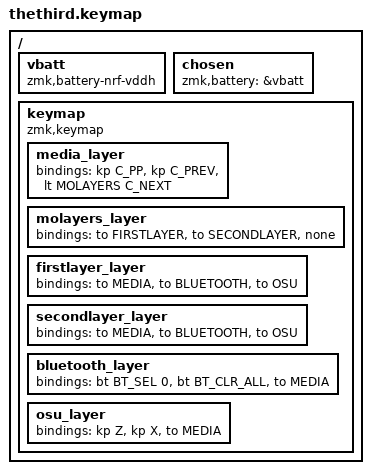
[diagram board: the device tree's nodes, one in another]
#include <behaviors.dtsi>
#include <dt-bindings/zmk/keys.h>
#include <dt-bindings/zmk/bt.h>
#include <dt-bindings/zmk/outputs.h>
#include <dt-bindings/zmk/ext_power.h>

#define MEDIA 0
#define MOLAYERS 1
#define FIRSTLAYER 2
#define SECONDLAYER 3
#define BLUETOOTH 4
#define OSU 5

/ {
    vbatt: vbatt {
                compatible = "zmk,battery-nrf-vddh";
        };
        chosen {
                zmk,battery = &vbatt;
        };

    keymap {
        compatible = "zmk,keymap";

        media_layer { //0
                bindings = <
                        &kp C_PP        &kp C_PREV      &lt MOLAYERS C_NEXT
                >;
        };

        molayers_layer { //1
                bindings = <
                        &to FIRSTLAYER  &to SECONDLAYER &none
                >;
        };

        firstlayer_layer { //2
                bindings = <
                        &to MEDIA       &to BLUETOOTH   &to OSU
                >;
        };

        secondlayer_layer { //3
                bindings = <
                        &to MEDIA       &to BLUETOOTH   &to OSU
                >;
        };

        bluetooth_layer { //4
                bindings = <
                        &bt BT_SEL 0    &bt BT_CLR_ALL  &to MEDIA 
                >;
        };

        osu_layer { //5
                bindings = <
                        &kp Z           &kp X           &to MEDIA
                >;
        };
    };
};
